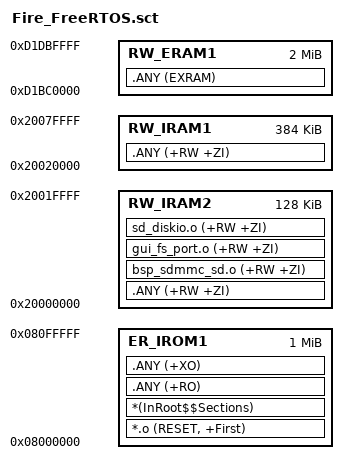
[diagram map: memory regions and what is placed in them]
; *************************************************************
; *** Scatter-Loading Description File generated by uVision ***
; *************************************************************

LR_IROM1 0x08000000 0x00100000  {    ; load region size_region
  ER_IROM1 0x08000000 0x00100000  {  ; load address = execution address
   *.o (RESET, +First)
   *(InRoot$$Sections)
   .ANY (+RO)
   .ANY (+XO)
  }
  RW_IRAM1 0x20020000 0x00060000  {  ; RW data
   .ANY (+RW +ZI)

  }
  RW_IRAM2 0x20000000 0x00020000  {	 ; 未使能cache区域
   .ANY (+RW +ZI)
   bsp_sdmmc_sd.o (+RW +ZI)
   gui_fs_port.o (+RW +ZI)
   sd_diskio.o (+RW +ZI)
   
  }
  
  RW_ERAM1 (0xD1BC0000) 0x00200000 {  ; 外部SDRAM未使能cache区域  //100000
  ;*.o (HEAP)          选择堆区
   .ANY (EXRAM)				;选择EXRAM节区
  }
}

